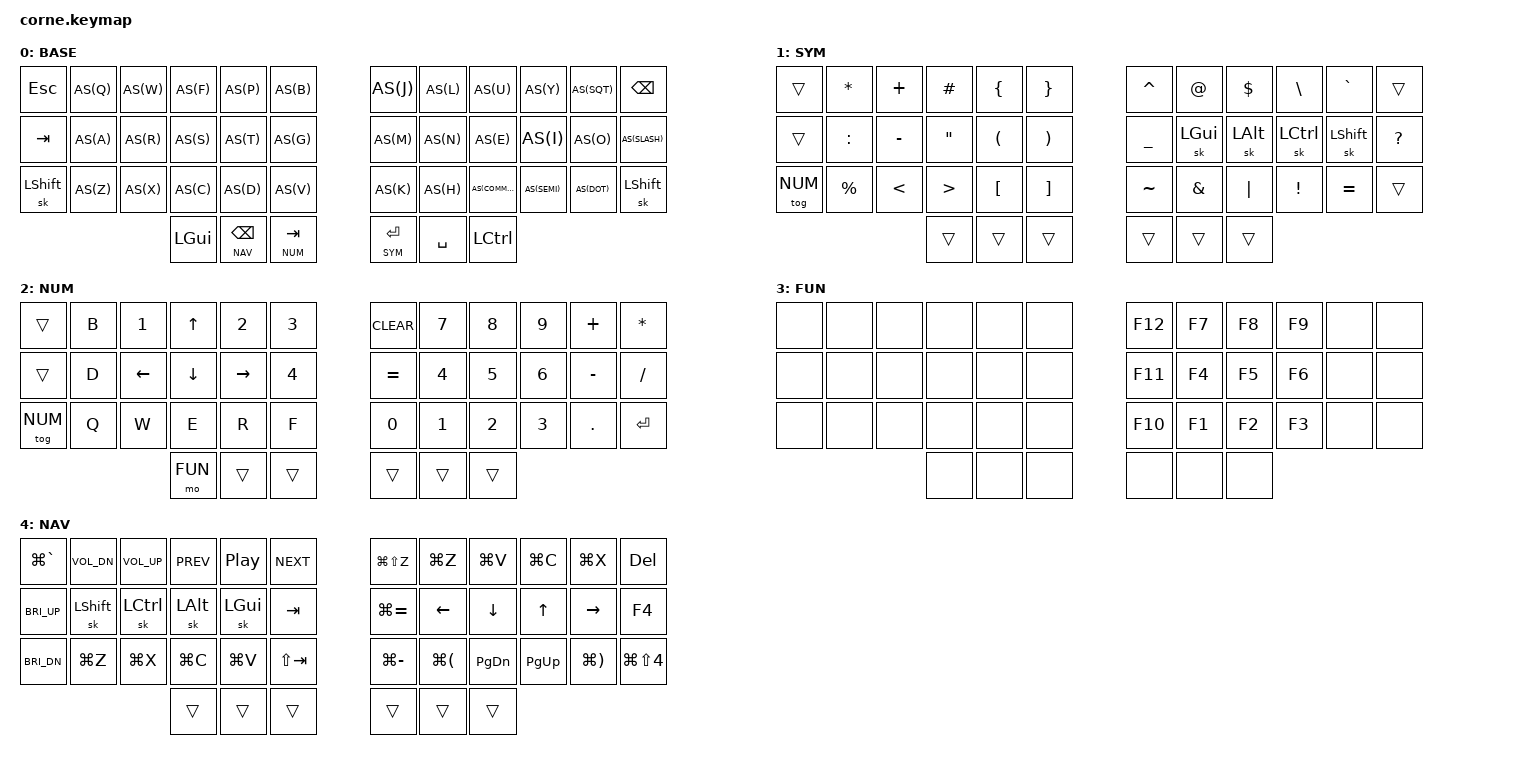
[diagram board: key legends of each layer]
/*
 * Copyright (c) 2020 The ZMK Contributors
 *
 * SPDX-License-Identifier: MIT
 */

#include <behaviors.dtsi>
#include <dt-bindings/zmk/keys.h>
#include <dt-bindings/zmk/bt.h>

#define AS(keycode) &as LS(keycode) keycode     // Autoshift Macro

#define CMK 0
#define SYM 1
#define NUM 2
#define FUN 3
#define NAV 4

&caps_word {
   continue-list = <UNDERSCORE MINUS BACKSPACE>;
};

/ {
    behaviors {
        as: auto_shift {
            compatible = "zmk,behavior-hold-tap";
            label = "AUTO_SHIFT";
            #binding-cells = <2>;
            tapping_term_ms = <185>;
            quick_tap_ms = <0>;
            flavor = "tap-preferred";
            bindings = <&kp>, <&kp>;
        };
    };
};

/ {
        keymap {
                compatible = "zmk,keymap";

                colemak_layer {
                  label = "BASE";
// ---------------------------------------------------------------------------
// | ESC   |  Q  |  W  |  F  |  P       |  B      | |  J      |  L  |  U  |  Y  |  '  |BSPC |
// | TAB   |  A  |  R  |  S  |  T       |  G      | |  M      |  N  |  E  |  I  |  O  |  /  |
// | SHIFT |  Z  |  X  |  C  |  D       |  V      | |  K      |  H  |  ,  |  ;  |  .  |SHIFT|
//                     | CTRL|BSPC -NAV-|TAB -NUM-| |RET -SYM-|SPACE| CMD |
                        bindings = <
   &kp ESC   AS(Q) AS(W) AS(F)     AS(P)   AS(B)      AS(J)     AS(L)       AS(U)     AS(Y)    AS(SQT) &kp BSPC
   &kp TAB   AS(A) AS(R) AS(S)     AS(T)   AS(G)      AS(M)     AS(N)       AS(E)     AS(I)    AS(O)   AS(SLASH)
   &sk LSHFT AS(Z) AS(X) AS(C)     AS(D)   AS(V)      AS(K)     AS(H)       AS(COMMA) AS(SEMI) AS(DOT) &sk LSHFT
                         &kp LGUI  &lt NAV BSPC &lt NUM TAB     &lt SYM RET &kp SPACE &kp LCTRL
                        >;
                };
                symbol_layer {
                  label = "SYM";
// ---------------------------------------------------------------------------
// |     |  *  |  +  |  #  |  {  |  }  | |  ^  |  @  |  $  |  \  |  `  |     |
// |     |  :  |  -  |  "  |  (  |  )  | |  _  | CMD | ALT | CTRL|SHIFT|  ?  |
// |     |-FUN-|  <  |  >  |  [  |  ]  | |  ~  |  &  |  |  |  !  |  -  |     |
//                   | OPT |_SYM_|SPACE| | RET | ESC | CMD |
                        bindings = <
   &trans   &kp STAR  &kp PLUS  &kp HASH &kp LBRC &kp RBRC    &kp CARET &kp AT   &kp DOLLAR &kp BSLH  &kp GRAVE &trans
   &trans   &kp COLON &kp MINUS &kp DQT  &kp LPAR &kp RPAR    &kp UNDER &sk LGUI &sk LALT   &sk LCTRL &sk LSHIFT &kp QMARK
   &tog NUM &kp PRCNT &kp LT    &kp GT   &kp LBKT &kp RBKT    &kp TILDE &kp AMPS &kp PIPE   &kp EXCL  &kp EQUAL &trans
                              &trans    &trans    &trans    &trans    &trans &trans
                        >;
                };
                number_layer {
                  label = "NUM";
// ---------------------------------------------------------------------------
// |     |  B  |  1   |  UP  |  2  |  3  | |CLEAR|  7  |  8  |  9  |  +  |  *  |
// |     |  D  | LEFT | DOWN |RIGHT|  4  | |  =  |  4  |  5  |  6  |  -  |  /  |
// |     |  Q  |  W   |  E   |  R  |  F  | |  0  |  1  |  2  |  3  |  .  | RET |
//                    |      |-FUN-| SPC | | RET |_NUM_| CMD |
// * Note: could do FN/globe key using CAPSLOCK as substitute:
//                         &trans   &sk CAPS  &trans     &trans    &trans &trans
                        bindings = <
   &trans   &kp B &kp N1   &kp UP   &kp N2    &kp N3    &kp CLEAR &kp N7 &kp N8 &kp N9 &kp PLUS  &kp STAR
   &trans   &kp D &kp LEFT &kp DOWN &kp RIGHT &kp N4    &kp EQUAL &kp N4 &kp N5 &kp N6 &kp MINUS &kp SLASH
   &tog NUM &kp Q &kp W    &kp E    &kp R     &kp F     &kp N0    &kp N1 &kp N2 &kp N3 &kp DOT   &kp RET
                         &mo FUN  &trans    &trans    &trans    &trans &trans
                        >;
                };
                fun_layer {
                  label = "FUN";
// ---------------------------------------------------------------------------
// |     |     | F 6 | F 5 | F 4 | F10 | | BT0 | BT1 | USB | BLE |     |     |
// |     |CAPSL| F 3 | F 2 | F 1 | F11 | |VMUTE|VOLDN|VOLUP|BRIDN|BRIUP|     |
// |     |_FUN_| F 9 | F 8 | F 7 | F12 | | <!> | <!> |SLEEP|-!!!-|<LCK>|
//                   | OPT |_SYM_| SPC | | RET |<LCK>| CMD |
                        bindings = <
   &none &none &none &none &none &none    &kp F12 &kp F7 &kp F8 &kp F9 &none &none
   &none &none &none &none &none &none    &kp F11 &kp F4 &kp F5 &kp F6 &none &none
   &none &none &none &none &none &none    &kp F10 &kp F1 &kp F2 &kp F3 &none &none
                     &none &none &none    &none   &none  &none
                        >;
                };
                nav_layer {
                  label = "NAV";
// ---------------------------------------------------------------------------
// | CMD+`  |C_NEXT|C_BRI_DN|C_BRI_UP|C_NEXT| C_PP    | |redo  | undo |paste|copy | cut | DEL |
// |C_VOL_UP| SHIFT| CTRL   | ALT    | CMD  | TAB     | |CMD + | LFT  | DWN | UP  |RIGHT|divvy|
// |C_VOL_DN| undo |  cut   | copy   | paste|shift+TAB| |CMD - | BACK |PG_DN|PG_UP| FWD |PrScr|
//                          |        |      |         | |      |      |     |
                        bindings = <
   &kp LG(GRAVE) &kp C_VOL_DN &kp C_VOL_UP &kp C_PREV &kp C_PP  &kp C_NEXT     &kp LG(LS(Z)) &kp LG(Z)    &kp LG(V) &kp LG(C) &kp LG(X)    &kp DEL
   &kp C_BRI_UP  &sk LSHIFT   &sk LCTRL    &sk LALT   &sk LGUI  &kp TAB        &kp LG(EQUAL) &kp LEFT     &kp DOWN  &kp UP    &kp RIGHT    &kp F4
   &kp C_BRI_DN  &kp LG(Z)    &kp LG(X)    &kp LG(C)  &kp LG(V) &kp LS(TAB)    &kp LG(MINUS) &kp LG(LPAR) &kp PG_DN &kp PG_UP &kp LG(RPAR) &kp LG(LS(N4))
                                           &trans     &trans    &trans         &trans &trans &trans
                        >;
                };
        };
};
